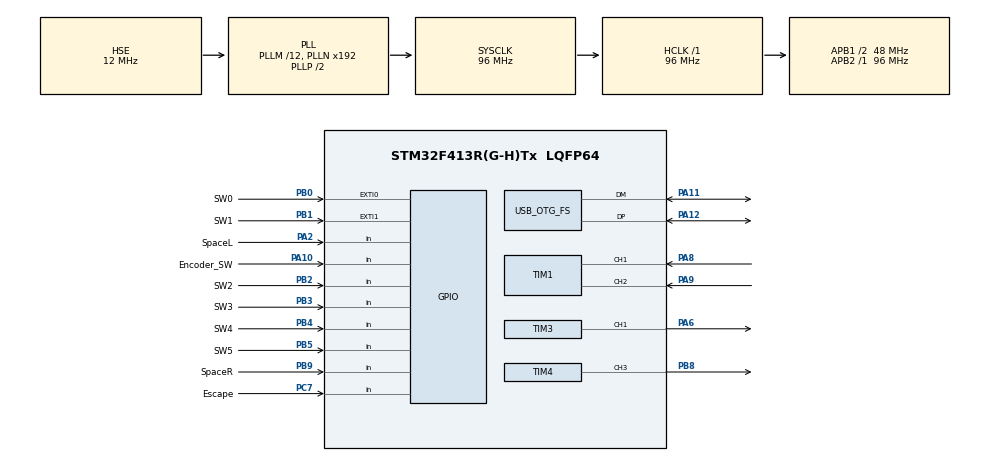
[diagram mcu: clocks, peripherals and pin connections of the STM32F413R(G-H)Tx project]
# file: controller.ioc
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Dma.Request0=TIM3_CH1/TRIG
Dma.Request1=TIM4_CH3
Dma.TIM3_CH1/TRIG.0.Direction=DMA_MEMORY_TO_PERIPH
Dma.TIM3_CH1/TRIG.0.FIFOMode=DMA_FIFOMODE_DISABLE
Dma.TIM3_CH1/TRIG.0.Instance=DMA1_Stream4
Dma.TIM3_CH1/TRIG.0.MemDataAlignment=DMA_MDATAALIGN_HALFWORD
Dma.TIM3_CH1/TRIG.0.MemInc=DMA_MINC_ENABLE
Dma.TIM3_CH1/TRIG.0.Mode=DMA_NORMAL
Dma.TIM3_CH1/TRIG.0.PeriphDataAlignment=DMA_PDATAALIGN_HALFWORD
Dma.TIM3_CH1/TRIG.0.PeriphInc=DMA_PINC_DISABLE
Dma.TIM3_CH1/TRIG.0.Priority=DMA_PRIORITY_LOW
Dma.TIM4_CH3.1.Direction=DMA_MEMORY_TO_PERIPH
Dma.TIM4_CH3.1.FIFOMode=DMA_FIFOMODE_DISABLE
Dma.TIM4_CH3.1.Instance=DMA1_Stream7
Dma.TIM4_CH3.1.MemDataAlignment=DMA_MDATAALIGN_HALFWORD
Dma.TIM4_CH3.1.MemInc=DMA_MINC_ENABLE
Dma.TIM4_CH3.1.Mode=DMA_NORMAL
Dma.TIM4_CH3.1.PeriphDataAlignment=DMA_PDATAALIGN_HALFWORD
Dma.TIM4_CH3.1.PeriphInc=DMA_PINC_DISABLE
Dma.TIM4_CH3.1.Priority=DMA_PRIORITY_HIGH
Mcu.Family=STM32F4
Mcu.Name=STM32F413R(G-H)Tx
Mcu.Package=LQFP64
NVIC.DMA1_Stream4_IRQn=true\:0\:0\:false\:false\:true\:false\:true\:true
NVIC.DMA1_Stream7_IRQn=true\:0\:0\:false\:false\:true\:false\:true\:true
NVIC.OTG_FS_IRQn=true\:0\:0\:false\:false\:true\:false\:true\:true
NVIC.PriorityGroup=NVIC_PRIORITYGROUP_4
NVIC.TIM6_DAC_IRQn=true\:0\:0\:false\:false\:true\:true\:true\:true
PA10.GPIO_Label=Encoder_SW
PA10.GPIO_PuPd=GPIO_PULLUP
PA10.Signal=GPIO_Input
PA11.Mode=Device_Only
PA11.Signal=USB_OTG_FS_DM
PA12.Mode=Device_Only
PA12.Signal=USB_OTG_FS_DP
PA13.Mode=Serial_Wire
PA13.Signal=SYS_JTMS-SWDIO
PA14.Mode=Serial_Wire
PA14.Signal=SYS_JTCK-SWCLK
PA2.GPIO_Label=SpaceL
PA2.GPIO_PuPd=GPIO_PULLUP
PA2.Signal=GPIO_Input
PA6.Signal=S_TIM3_CH1
PA8.Signal=S_TIM1_CH1
PA9.Signal=S_TIM1_CH2
PB0.GPIO_Label=SW0
PB0.GPIO_PuPd=GPIO_PULLUP
PB0.Signal=GPXTI0
PB1.GPIO_Label=SW1
PB1.GPIO_PuPd=GPIO_PULLUP
PB1.Signal=GPXTI1
PB2.GPIO_Label=SW2
PB2.GPIO_PuPd=GPIO_PULLUP
PB2.Signal=GPIO_Input
PB3.GPIO_Label=SW3
PB3.GPIO_PuPd=GPIO_PULLUP
PB3.Signal=GPIO_Input
PB4.GPIO_Label=SW4
PB4.GPIO_PuPd=GPIO_PULLUP
PB4.Signal=GPIO_Input
PB5.GPIO_Label=SW5
PB5.GPIO_PuPd=GPIO_PULLUP
PB5.Signal=GPIO_Input
PB8.Signal=S_TIM4_CH3
PB9.GPIO_Label=SpaceR
PB9.GPIO_PuPd=GPIO_PULLUP
PB9.Signal=GPIO_Input
PC7.GPIO_Label=Escape
PC7.GPIO_PuPd=GPIO_PULLUP
PC7.Signal=GPIO_Input
PH0\ -\ OSC_IN.Mode=HSE-External-Oscillator
PH0\ -\ OSC_IN.Signal=RCC_OSC_IN
PH1\ -\ OSC_OUT.Mode=HSE-External-Oscillator
PH1\ -\ OSC_OUT.Signal=RCC_OSC_OUT
ProjectManager.HeapSize=0x200
ProjectManager.StackSize=0x400
ProjectManager.TargetToolchain=Makefile
RCC.AHBFreq_Value=96000000
RCC.APB1CLKDivider=RCC_HCLK_DIV2
RCC.APB1Freq_Value=48000000
RCC.APB1TimFreq_Value=96000000
RCC.APB2Freq_Value=96000000
RCC.APB2TimFreq_Value=96000000
RCC.CortexFreq_Value=96000000
RCC.HCLKFreq_Value=96000000
RCC.HSE_VALUE=12000000
RCC.PLLM=12
RCC.PLLQ=4
RCC.SYSCLKFreq_VALUE=96000000
RCC.SYSCLKSource=RCC_SYSCLKSOURCE_PLLCLK
RCC.USBFreq_Value=48000000
RCC.VCOOutputFreq_Value=192000000
SH.S_TIM1_CH1.0=TIM1_CH1,Encoder_Interface
SH.S_TIM1_CH2.0=TIM1_CH2,Encoder_Interface
SH.S_TIM3_CH1.0=TIM3_CH1,PWM Generation1 CH1
SH.S_TIM4_CH3.0=TIM4_CH3,PWM Generation3 CH3
TIM1.EncoderMode=TIM_ENCODERMODE_TI12
TIM3.Channel-PWM\ Generation1\ CH1=TIM_CHANNEL_1
TIM3.Period=48-1
TIM3.Prescaler=1
TIM4.Channel-PWM\ Generation3\ CH3=TIM_CHANNEL_3
TIM4.Period=48-1
TIM4.Prescaler=1
TIM6.Period=1000-1
TIM6.Prescaler=9600-1
USB_DEVICE.CLASS_NAME_FS=HID
USB_DEVICE.HID_FS_BINTERVAL=0x1
USB_DEVICE.VirtualMode=Hid
USB_DEVICE.VirtualModeFS=Hid_FS
USB_OTG_FS.VirtualMode=Device_Only
VP_TIM4_VS_ClockSourceINT.Mode=Internal
VP_TIM6_VS_ClockSourceINT.Mode=Enable_Timer
VP_USB_DEVICE_VS_USB_DEVICE_HID_FS.Mode=HID_FS
board=custom

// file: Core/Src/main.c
/* USER CODE BEGIN Header */
/**
  ******************************************************************************
  * @file           : main.c
  * @brief          : Main program body
  ******************************************************************************
  * @attention
  *
  * Copyright (c) 2025 STMicroelectronics.
  * All rights reserved.
  *
  * This software is licensed under terms that can be found in the LICENSE file
  * in the root directory of this software component.
  * If no LICENSE file comes with this software, it is provided AS-IS.
  *
  ******************************************************************************
  */
/* USER CODE END Header */
#include "main.h"
#include "dma.h"
#include "tim.h"
#include "usb_device.h"
#include "gpio.h"

/* USER CODE BEGIN Includes */
#include "keyboard.hpp"
#include "led.hpp"
/* USER CODE END Includes */

void SystemClock_Config(void);
/* USER CODE BEGIN PFP */
void cycle_callback_start();
void cycle_callback();
/* USER CODE END PFP */

int main(void)
{

  /* MCU Configuration--------------------------------------------------------*/

  /* Reset of all peripherals, Initializes the Flash interface and the Systick. */
  HAL_Init();

  /* Configure the system clock */
  SystemClock_Config();

  /* Initialize all configured peripherals */
  MX_GPIO_Init();
  MX_DMA_Init();
  MX_TIM6_Init();
  MX_USB_DEVICE_Init();
  MX_TIM1_Init();
  MX_TIM3_Init();
  MX_TIM4_Init();
  /* USER CODE BEGIN 2 */
  keyboard.init();
  cycle_callback_start();
  /* USER CODE END 2 */

  /* Infinite loop */
  while (1)
  {

  }
}

void SystemClock_Config(void)
{
  RCC_OscInitTypeDef RCC_OscInitStruct = {0};
  RCC_ClkInitTypeDef RCC_ClkInitStruct = {0};

  /** Configure the main internal regulator output voltage
  */
  __HAL_RCC_PWR_CLK_ENABLE();
  __HAL_PWR_VOLTAGESCALING_CONFIG(PWR_REGULATOR_VOLTAGE_SCALE1);

  /** Initializes the RCC Oscillators according to the specified parameters
  * in the RCC_OscInitTypeDef structure.
  */
  RCC_OscInitStruct.OscillatorType = RCC_OSCILLATORTYPE_HSE;
  RCC_OscInitStruct.HSEState = RCC_HSE_ON;
  RCC_OscInitStruct.PLL.PLLState = RCC_PLL_ON;
  RCC_OscInitStruct.PLL.PLLSource = RCC_PLLSOURCE_HSE;
  RCC_OscInitStruct.PLL.PLLM = 12;
  RCC_OscInitStruct.PLL.PLLN = 192;
  RCC_OscInitStruct.PLL.PLLP = RCC_PLLP_DIV2;
  RCC_OscInitStruct.PLL.PLLQ = 4;
  RCC_OscInitStruct.PLL.PLLR = 2;
  if (HAL_RCC_OscConfig(&RCC_OscInitStruct) != HAL_OK)
  {
    Error_Handler();
  }

  /** Initializes the CPU, AHB and APB buses clocks
  */
  RCC_ClkInitStruct.ClockType = RCC_CLOCKTYPE_HCLK|RCC_CLOCKTYPE_SYSCLK
                              |RCC_CLOCKTYPE_PCLK1|RCC_CLOCKTYPE_PCLK2;
  RCC_ClkInitStruct.SYSCLKSource = RCC_SYSCLKSOURCE_PLLCLK;
  RCC_ClkInitStruct.AHBCLKDivider = RCC_SYSCLK_DIV1;
  RCC_ClkInitStruct.APB1CLKDivider = RCC_HCLK_DIV2;
  RCC_ClkInitStruct.APB2CLKDivider = RCC_HCLK_DIV1;

  if (HAL_RCC_ClockConfig(&RCC_ClkInitStruct, FLASH_LATENCY_3) != HAL_OK)
  {
    Error_Handler();
  }
}

void Error_Handler(void)
{
  __disable_irq();
  while (1)
  {
  }
}
